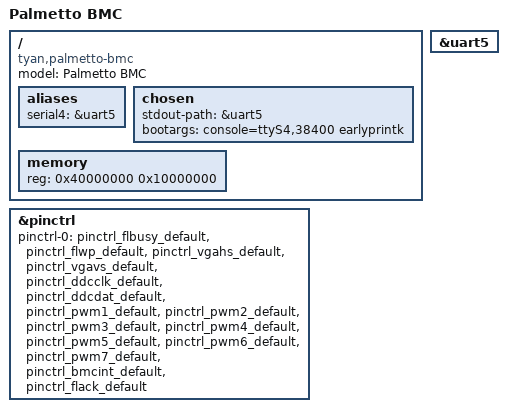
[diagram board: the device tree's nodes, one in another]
/dts-v1/;

#include "aspeed-g4.dtsi"

/ {
	model = "Palmetto BMC";
	compatible = "tyan,palmetto-bmc", "aspeed,ast2400";

	aliases {
		serial4 = &uart5;
	};

	chosen {
		stdout-path = &uart5;
		bootargs = "console=ttyS4,38400 earlyprintk";
	};

	memory {
		reg = <0x40000000 0x10000000>;
	};
};

&pinctrl {
	pinctrl-names = "default";
	pinctrl-0 = <&pinctrl_flbusy_default &pinctrl_flwp_default
			&pinctrl_vgahs_default &pinctrl_vgavs_default
			&pinctrl_ddcclk_default &pinctrl_ddcdat_default

			&pinctrl_pwm1_default &pinctrl_pwm2_default
			&pinctrl_pwm3_default &pinctrl_pwm4_default
			&pinctrl_pwm5_default &pinctrl_pwm6_default
			&pinctrl_pwm7_default

			&pinctrl_bmcint_default &pinctrl_flack_default>;
};

&uart5 {
	status = "okay";
};
